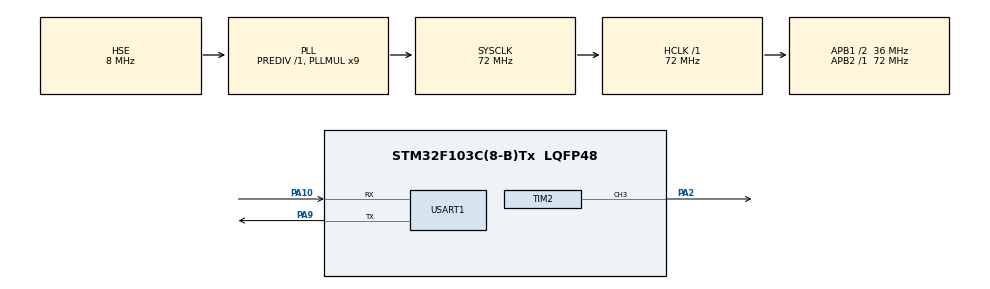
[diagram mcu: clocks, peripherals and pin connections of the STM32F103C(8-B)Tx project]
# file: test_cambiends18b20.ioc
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Mcu.Family=STM32F1
Mcu.Name=STM32F103C(8-B)Tx
Mcu.Package=LQFP48
NVIC.PriorityGroup=NVIC_PRIORITYGROUP_4
NVIC.TIM1_UP_IRQn=true\:0\:0\:false\:false\:true\:true
NVIC.TIM2_IRQn=true\:0\:0\:false\:false\:true\:true
NVIC.USART1_IRQn=true\:1\:0\:true\:false\:true\:true
PA10.Mode=Asynchronous
PA10.Signal=USART1_RX
PA13.Mode=Serial_Wire
PA13.Signal=SYS_JTMS-SWDIO
PA14.Mode=Serial_Wire
PA14.Signal=SYS_JTCK-SWCLK
PA2.Signal=S_TIM2_CH3
PA9.Mode=Asynchronous
PA9.Signal=USART1_TX
PD0-OSC_IN.Mode=HSE-External-Oscillator
PD0-OSC_IN.Signal=RCC_OSC_IN
PD1-OSC_OUT.Mode=HSE-External-Oscillator
PD1-OSC_OUT.Signal=RCC_OSC_OUT
ProjectManager.HeapSize=0x200
ProjectManager.StackSize=0x400
ProjectManager.TargetToolchain=MDK-ARM V5
RCC.AHBFreq_Value=72000000
RCC.APB1CLKDivider=RCC_HCLK_DIV2
RCC.APB1Freq_Value=36000000
RCC.APB1TimFreq_Value=72000000
RCC.APB2Freq_Value=72000000
RCC.APB2TimFreq_Value=72000000
RCC.HCLKFreq_Value=72000000
RCC.PLLMUL=RCC_PLL_MUL9
RCC.PLLSourceVirtual=RCC_PLLSOURCE_HSE
RCC.SYSCLKFreq_VALUE=72000000
RCC.SYSCLKSource=RCC_SYSCLKSOURCE_PLLCLK
RCC.USBFreq_Value=72000000
SH.S_TIM2_CH3.0=TIM2_CH3,PWM Generation3 CH3
TIM1.Period=19
TIM1.Prescaler=3599
TIM2.Channel-PWM\ Generation3\ CH3=TIM_CHANNEL_3
TIM2.Period=8999
TIM2.Prescaler=7
USART1.VirtualMode=VM_ASYNC
VP_TIM1_VS_ClockSourceINT.Mode=Internal
VP_TIM2_VS_ClockSourceINT.Mode=Internal
board=test_cambiends18b20

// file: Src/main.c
/**
  ******************************************************************************
  * @file           : main.c
  * @brief          : Main program body
  ******************************************************************************
  ** This notice applies to any and all portions of this file
  * that are not between comment pairs USER CODE BEGIN and
  * USER CODE END. Other portions of this file, whether
  * inserted by the user or by software development tools
  * are owned by their respective copyright owners.
  *
  * COPYRIGHT(c) 2019 STMicroelectronics
  *
  * Redistribution and use in source and binary forms, with or without modification,
  * are permitted provided that the following conditions are met:
  *   1. Redistributions of source code must retain the above copyright notice,
  *      this list of conditions and the following disclaimer.
  *   2. Redistributions in binary form must reproduce the above copyright notice,
  *      this list of conditions and the following disclaimer in the documentation
  *      and/or other materials provided with the distribution.
  *   3. Neither the name of STMicroelectronics nor the names of its contributors
  *      may be used to endorse or promote products derived from this software
  *      without specific prior written permission.
  *
  * THIS SOFTWARE IS PROVIDED BY THE COPYRIGHT HOLDERS AND CONTRIBUTORS "AS IS"
  * AND ANY EXPRESS OR IMPLIED WARRANTIES, INCLUDING, BUT NOT LIMITED TO, THE
  * IMPLIED WARRANTIES OF MERCHANTABILITY AND FITNESS FOR A PARTICULAR PURPOSE ARE
  * DISCLAIMED. IN NO EVENT SHALL THE COPYRIGHT HOLDER OR CONTRIBUTORS BE LIABLE
  * FOR ANY DIRECT, INDIRECT, INCIDENTAL, SPECIAL, EXEMPLARY, OR CONSEQUENTIAL
  * DAMAGES (INCLUDING, BUT NOT LIMITED TO, PROCUREMENT OF SUBSTITUTE GOODS OR
  * SERVICES; LOSS OF USE, DATA, OR PROFITS; OR BUSINESS INTERRUPTION) HOWEVER
  * CAUSED AND ON ANY THEORY OF LIABILITY, WHETHER IN CONTRACT, STRICT LIABILITY,
  * OR TORT (INCLUDING NEGLIGENCE OR OTHERWISE) ARISING IN ANY WAY OUT OF THE USE
  * OF THIS SOFTWARE, EVEN IF ADVISED OF THE POSSIBILITY OF SUCH DAMAGE.
  *
  ******************************************************************************
  */
#include "main.h"
#include "stm32f1xx_hal.h"

/* USER CODE BEGIN Includes */
#include "dwt_stm32_delay.h"
#include "stdlib.h"
#include "string.h"
/* USER CODE END Includes */

TIM_HandleTypeDef htim1;
TIM_HandleTypeDef htim2;

UART_HandleTypeDef huart1;

/* USER CODE BEGIN PV */
/* Private variables ---------------------------------------------------------*/
char Rx_indx, Rx_Buffer[20],Rx_data[2];
double set_Temp=123;
double Temp=0;
double NDset;

static float err_p=0; // sai so khвu p
static float ui_p=0;
float err;
double up,ui,ud;
uint16_t	pwm;
float Kp=200;
float Ki=2;
float	Kd=15.0;
float T=0.01;

/* USER CODE END PV */

void SystemClock_Config(void);
static void MX_GPIO_Init(void);
static void MX_USART1_UART_Init(void);
static void MX_TIM1_Init(void);
static void MX_TIM2_Init(void);

void HAL_TIM_MspPostInit(TIM_HandleTypeDef *htim);

/* USER CODE BEGIN PFP */
/* Private function prototypes -----------------------------------------------*/

/* USER CODE END PFP */

/* USER CODE BEGIN 0 */

/*HAM GUI DATA */
_ARMABI int fputc(int c, FILE * stream)
 {
	 HAL_UART_Transmit(&huart1,(uint8_t *)&c,1,100);
 }
 /*HAM NGAT UART1 DE NHAN DATA*/
 void HAL_UART_RxCpltCallback(UART_HandleTypeDef *huart)
	{
		uint8_t i;
		if(huart->Instance == USART1) //uart1
		{
				if(Rx_indx==0) {for (i=0;i<20;i++) Rx_Buffer[i] = 0;}

				switch(Rx_data[0])
					{
            case 's':
						{
                NDset = atof(Rx_Buffer);
                memset(Rx_Buffer, 0, sizeof(Rx_Buffer));
                Rx_indx = 0;
						   	printf("T%f",NDset);
                break;
						}
            case '0':
						{

							break;

						}
            case '1':
            case '2':
            case '3':
            case '4':
            case '5':
            case '6':
            case '7':
            case '8':
            case '9':
            case '.':
            case '-':
                Rx_Buffer[Rx_indx++] |= Rx_data[0];
                break;
            default:
                break;
        }
				HAL_UART_Receive_IT(&huart1,(uint8_t*)Rx_data,1);
		}
	}

 // DOC CAM BIEN NHIET DO
 // CAM BIEN DOC O TAN SO XUNG CLOCK 72MHz
  GPIO_InitTypeDef GPIO_InitStruct;
void gpio_set_input (void)
{
  GPIO_InitStruct.Pin = GPIO_PIN_1;
  GPIO_InitStruct.Mode = GPIO_MODE_INPUT;
  GPIO_InitStruct.Pull = GPIO_PULLUP;
  HAL_GPIO_Init(GPIOA, &GPIO_InitStruct);
}

void gpio_set_output (void)
{
  GPIO_InitStruct.Pin = GPIO_PIN_1;
  GPIO_InitStruct.Mode = GPIO_MODE_OUTPUT_PP;
  GPIO_InitStruct.Pull = GPIO_NOPULL;
  GPIO_InitStruct.Speed = GPIO_SPEED_FREQ_LOW;
  HAL_GPIO_Init(GPIOA, &GPIO_InitStruct);
}

uint8_t check =2, temp_l, temp_h;
uint16_t temp;
float temperature;

uint8_t ds18b20_init (void)
{
	gpio_set_output ();   // set the pin as output
	HAL_GPIO_WritePin (GPIOA, GPIO_PIN_1, 0);  // pull the pin low
	DWT_Delay_us (480);   // delay according to datasheet

	gpio_set_input ();    // set the pin as input
	DWT_Delay_us (80);    // delay according to datasheet

	if (!(HAL_GPIO_ReadPin (GPIOA, GPIO_PIN_1)))    // if the pin is low i.e the presence pulse is there
	{
		DWT_Delay_us (400);  // wait for 400 us
		return 0;
	}

	else
	{
		DWT_Delay_us (400);
		return 1;
	}
}

void write (uint8_t data)
{
	gpio_set_output ();   // set as output

	for (int i=0; i<8; i++)
	{

		if ((data & (1<<i))!=0)  // if the bit is high
		{
			// write 1

			gpio_set_output ();  // set as output
			HAL_GPIO_WritePin (GPIOA, GPIO_PIN_1, 0);  // pull the pin LOW
			DWT_Delay_us (1);  // wait for  us

			gpio_set_input ();  // set as input
			DWT_Delay_us (60);  // wait for 60 us
		}

		else  // if the bit is low
		{
			// write 0

			gpio_set_output ();
			HAL_GPIO_WritePin (GPIOA, GPIO_PIN_1, 0);  // pull the pin LOW
			DWT_Delay_us (60);  // wait for 60 us

			gpio_set_input ();
		}
	}
}

uint8_t read (void)
{
	uint8_t value=0;
	gpio_set_input ();

	for (int i=0;i<8;i++)
	{
		gpio_set_output ();   // set as output

		HAL_GPIO_WritePin (GPIOA, GPIO_PIN_1, 0);  // pull the data pin LOW
		DWT_Delay_us (2);  // wait for 2 us

		gpio_set_input ();  // set as input
		if (HAL_GPIO_ReadPin (GPIOA, GPIO_PIN_1))  // if the pin is HIGH
		{
			value |= 1<<i;  // read = 1
		}
		DWT_Delay_us (60);  // wait for 60 us
	}
	return value;
}

float readtemp(void)
{
      ds18b20_init();
      write (0xCC);  // skip ROM
      write (0x44);  // convert t

      DWT_Delay_us(8000);
      ds18b20_init();

      write (0xCC);  // skip ROM
      write (0xBE);  // Read Scratchpad

      uint8_t  temp_l = read();
      uint8_t temp_h = read();

      uint16_t temp = (temp_h<<8)|temp_l;

    float temperature = (float)temp/16;
      return temperature;
}
/*NGAT CHO TIMER 1 DE DO NHIET DO VA TINH PID*/
/*
void HAL_TIM_PeriodElapsedCallback(TIM_HandleTypeDef *htim)
{
	if(htim->Instance==TIM1)	// ngat do timer1 10ms
	{
		Temp=readtemp();
	//  printf("T%.1f\r\n",Temp);

		err=set_Temp-Temp;
		up=Kp*err;
		ud=Kd*(err-err_p)/T;
		ui=ui_p+Ki*err*T ;

		err_p=err;
		ui_p=ui;

		pwm=(uint16_t)(up+ud+ui);

	  if (pwm>8999)   pwm=8000;
		else if(pwm<0) pwm=0.0;

	//	__HAL_TIM_SET_COMPARE(&htim2,TIM_CHANNEL_3,pwm);

		printf("pwm = %d\r\n",pwm);
	}
}
*/

/* USER CODE END 0 */

int main(void)
{

  /* MCU Configuration----------------------------------------------------------*/

  /* Reset of all peripherals, Initializes the Flash interface and the Systick. */
  HAL_Init();

  /* Configure the system clock */
  SystemClock_Config();

  /* Initialize all configured peripherals */
  MX_GPIO_Init();
  MX_USART1_UART_Init();
  MX_TIM1_Init();
  MX_TIM2_Init();
  /* USER CODE BEGIN 2 */
	DWT_Delay_Init(); // CONFI DELAY
	//HAL_TIM_Base_Start_IT(&htim1); //ENABLE INTERRRUPT TIMER1
	//HAL_TIM_PWM_Start(&htim2,TIM_CHANNEL_3); // ENABLE PWM TIMER2
	HAL_UART_Receive_IT(&huart1,(uint8_t*)Rx_data,1);// nhan data bang ngat uart
  /* USER CODE END 2 */

  /* Infinite loop */
  while (1)
  {

  }

}

void SystemClock_Config(void)
{

  RCC_OscInitTypeDef RCC_OscInitStruct;
  RCC_ClkInitTypeDef RCC_ClkInitStruct;

    /**Initializes the CPU, AHB and APB busses clocks
    */
  RCC_OscInitStruct.OscillatorType = RCC_OSCILLATORTYPE_HSE;
  RCC_OscInitStruct.HSEState = RCC_HSE_ON;
  RCC_OscInitStruct.HSEPredivValue = RCC_HSE_PREDIV_DIV1;
  RCC_OscInitStruct.HSIState = RCC_HSI_ON;
  RCC_OscInitStruct.PLL.PLLState = RCC_PLL_ON;
  RCC_OscInitStruct.PLL.PLLSource = RCC_PLLSOURCE_HSE;
  RCC_OscInitStruct.PLL.PLLMUL = RCC_PLL_MUL9;
  if (HAL_RCC_OscConfig(&RCC_OscInitStruct) != HAL_OK)
  {
    _Error_Handler(__FILE__, __LINE__);
  }

    /**Initializes the CPU, AHB and APB busses clocks
    */
  RCC_ClkInitStruct.ClockType = RCC_CLOCKTYPE_HCLK|RCC_CLOCKTYPE_SYSCLK
                              |RCC_CLOCKTYPE_PCLK1|RCC_CLOCKTYPE_PCLK2;
  RCC_ClkInitStruct.SYSCLKSource = RCC_SYSCLKSOURCE_PLLCLK;
  RCC_ClkInitStruct.AHBCLKDivider = RCC_SYSCLK_DIV1;
  RCC_ClkInitStruct.APB1CLKDivider = RCC_HCLK_DIV2;
  RCC_ClkInitStruct.APB2CLKDivider = RCC_HCLK_DIV1;

  if (HAL_RCC_ClockConfig(&RCC_ClkInitStruct, FLASH_LATENCY_2) != HAL_OK)
  {
    _Error_Handler(__FILE__, __LINE__);
  }

    /**Configure the Systick interrupt time
    */
  HAL_SYSTICK_Config(HAL_RCC_GetHCLKFreq()/1000);

    /**Configure the Systick
    */
  HAL_SYSTICK_CLKSourceConfig(SYSTICK_CLKSOURCE_HCLK);

  /* SysTick_IRQn interrupt configuration */
  HAL_NVIC_SetPriority(SysTick_IRQn, 0, 0);
}

/* TIM1 init function */
static void MX_TIM1_Init(void)
{

  TIM_ClockConfigTypeDef sClockSourceConfig;
  TIM_MasterConfigTypeDef sMasterConfig;

  htim1.Instance = TIM1;
  htim1.Init.Prescaler = 3599;
  htim1.Init.CounterMode = TIM_COUNTERMODE_UP;
  htim1.Init.Period = 19;
  htim1.Init.ClockDivision = TIM_CLOCKDIVISION_DIV1;
  htim1.Init.RepetitionCounter = 0;
  htim1.Init.AutoReloadPreload = TIM_AUTORELOAD_PRELOAD_DISABLE;
  if (HAL_TIM_Base_Init(&htim1) != HAL_OK)
  {
    _Error_Handler(__FILE__, __LINE__);
  }

  sClockSourceConfig.ClockSource = TIM_CLOCKSOURCE_INTERNAL;
  if (HAL_TIM_ConfigClockSource(&htim1, &sClockSourceConfig) != HAL_OK)
  {
    _Error_Handler(__FILE__, __LINE__);
  }

  sMasterConfig.MasterOutputTrigger = TIM_TRGO_RESET;
  sMasterConfig.MasterSlaveMode = TIM_MASTERSLAVEMODE_DISABLE;
  if (HAL_TIMEx_MasterConfigSynchronization(&htim1, &sMasterConfig) != HAL_OK)
  {
    _Error_Handler(__FILE__, __LINE__);
  }

}

/* TIM2 init function */
static void MX_TIM2_Init(void)
{

  TIM_ClockConfigTypeDef sClockSourceConfig;
  TIM_MasterConfigTypeDef sMasterConfig;
  TIM_OC_InitTypeDef sConfigOC;

  htim2.Instance = TIM2;
  htim2.Init.Prescaler = 7;
  htim2.Init.CounterMode = TIM_COUNTERMODE_UP;
  htim2.Init.Period = 8999;
  htim2.Init.ClockDivision = TIM_CLOCKDIVISION_DIV1;
  htim2.Init.AutoReloadPreload = TIM_AUTORELOAD_PRELOAD_DISABLE;
  if (HAL_TIM_Base_Init(&htim2) != HAL_OK)
  {
    _Error_Handler(__FILE__, __LINE__);
  }

  sClockSourceConfig.ClockSource = TIM_CLOCKSOURCE_INTERNAL;
  if (HAL_TIM_ConfigClockSource(&htim2, &sClockSourceConfig) != HAL_OK)
  {
    _Error_Handler(__FILE__, __LINE__);
  }

  if (HAL_TIM_PWM_Init(&htim2) != HAL_OK)
  {
    _Error_Handler(__FILE__, __LINE__);
  }

  sMasterConfig.MasterOutputTrigger = TIM_TRGO_RESET;
  sMasterConfig.MasterSlaveMode = TIM_MASTERSLAVEMODE_DISABLE;
  if (HAL_TIMEx_MasterConfigSynchronization(&htim2, &sMasterConfig) != HAL_OK)
  {
    _Error_Handler(__FILE__, __LINE__);
  }

  sConfigOC.OCMode = TIM_OCMODE_PWM1;
  sConfigOC.Pulse = 0;
  sConfigOC.OCPolarity = TIM_OCPOLARITY_HIGH;
  sConfigOC.OCFastMode = TIM_OCFAST_DISABLE;
  if (HAL_TIM_PWM_ConfigChannel(&htim2, &sConfigOC, TIM_CHANNEL_3) != HAL_OK)
  {
    _Error_Handler(__FILE__, __LINE__);
  }

  HAL_TIM_MspPostInit(&htim2);

}

/* USART1 init function */
static void MX_USART1_UART_Init(void)
{

  huart1.Instance = USART1;
  huart1.Init.BaudRate = 115200;
  huart1.Init.WordLength = UART_WORDLENGTH_8B;
  huart1.Init.StopBits = UART_STOPBITS_1;
  huart1.Init.Parity = UART_PARITY_NONE;
  huart1.Init.Mode = UART_MODE_TX_RX;
  huart1.Init.HwFlowCtl = UART_HWCONTROL_NONE;
  huart1.Init.OverSampling = UART_OVERSAMPLING_16;
  if (HAL_UART_Init(&huart1) != HAL_OK)
  {
    _Error_Handler(__FILE__, __LINE__);
  }

}

/** Configure pins as
        * Analog
        * Input
        * Output
        * EVENT_OUT
        * EXTI
*/
static void MX_GPIO_Init(void)
{

  /* GPIO Ports Clock Enable */
  __HAL_RCC_GPIOD_CLK_ENABLE();
  __HAL_RCC_GPIOA_CLK_ENABLE();

}

void _Error_Handler(char *file, int line)
{
  while(1)
  {
  }
}

/************************ (C) COPYRIGHT STMicroelectronics *****END OF FILE****/
